AUTOSAR XML (schema 00051)
package /ApplicationECU_FlatView/SwComponentTypes
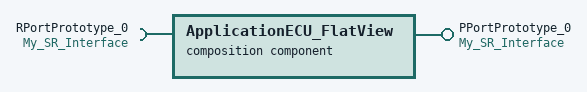
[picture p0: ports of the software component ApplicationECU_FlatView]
  composition sw component type ApplicationECU_FlatView
    provide port PPortPrototype_0: provided-interface=My_SR_Interface
    require port RPortPrototype_0: required-interface=My_SR_Interface
    component CPT_MySWC_ApplicationECU: type=MySWC
    delegate CPT_MySWC_ApplicationECU.PPortPrototype_0 <-> outer port PPortPrototype_0
    delegate CPT_MySWC_ApplicationECU.RPortPrototype_0 <-> outer port RPortPrototype_0
